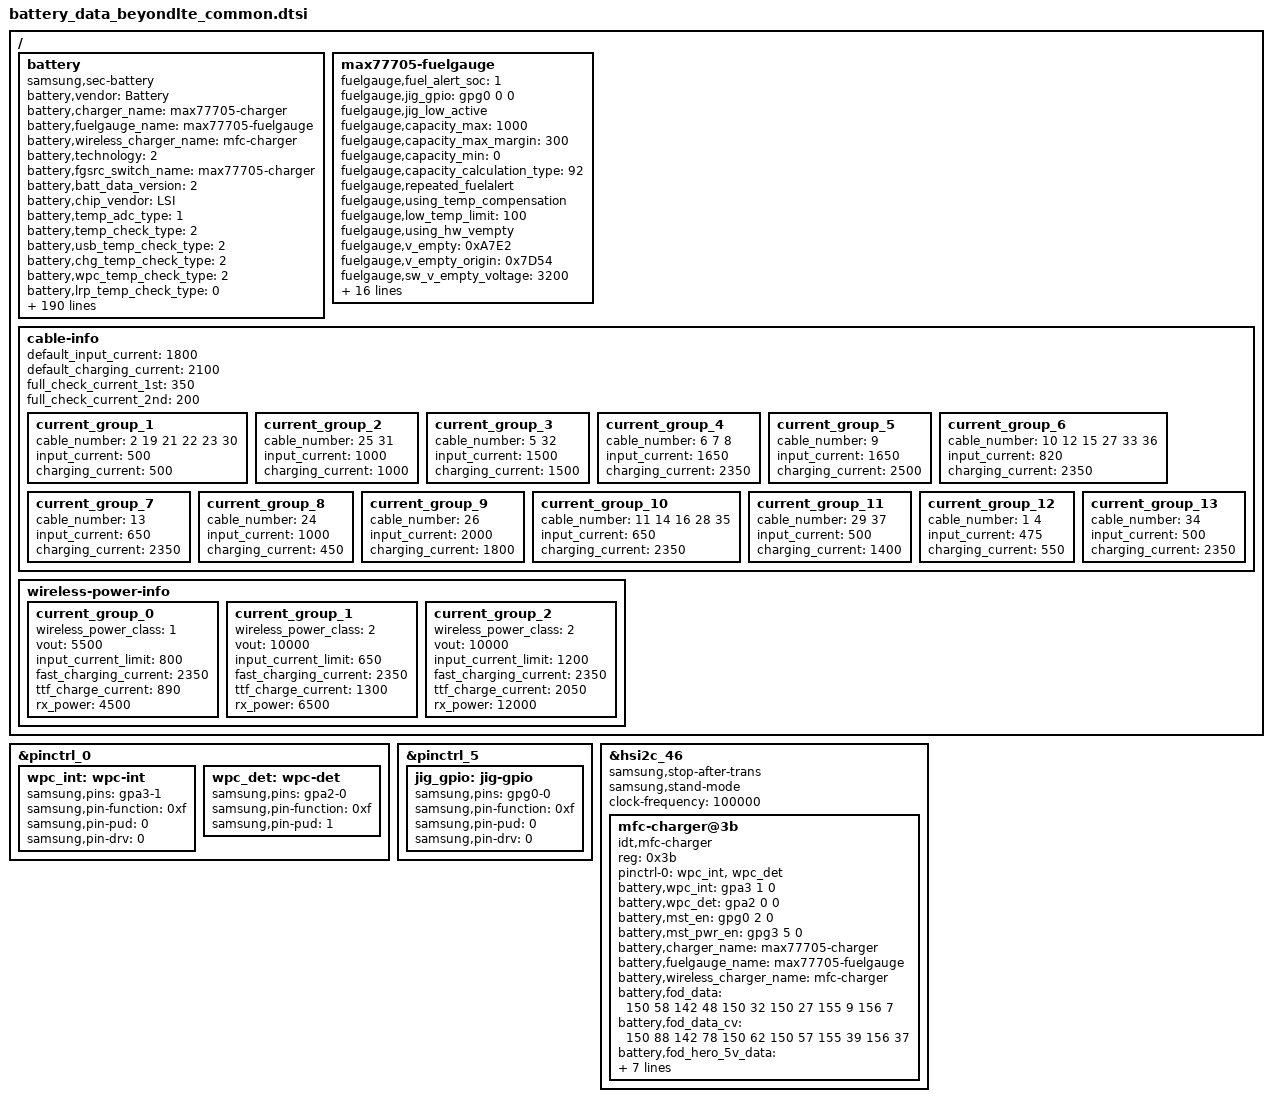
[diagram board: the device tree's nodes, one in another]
/*
 * SAMSUNG UNIVERSAL9820 board device tree source
 *
 * Copyright (c) 2018 Samsung Electronics Co., Ltd.
 *		http://www.samsung.com
 *
 * This program is free software; you can redistribute it and/or modify
 * it under the terms of the GNU General Public License version 2 as
 * published by the Free Software Foundation.
 */

/ {
	fragment@battery {
		target-path = "/";
		__overlay__ {
			battery {
				status = "okay";
				compatible = "samsung,sec-battery";

				pinctrl-names = "default";
				/* battery,irq_gpio = <&gpa1 6 0>; */

				battery,vendor = "Battery";
				battery,charger_name = "max77705-charger";
				battery,fuelgauge_name = "max77705-fuelgauge";
				battery,wireless_charger_name = "mfc-charger";
				battery,technology = <2>; /* POWER_SUPPLY_TECHNOLOGY_LION */
				battery,fgsrc_switch_name = "max77705-charger"; /* Fuelgauge voltage source */

				battery,batt_data_version = <2>;

				battery,chip_vendor = "LSI";
				battery,temp_adc_type = <1>; /* SEC_BATTERY_ADC_TYPE_AP */

				battery,temp_check_type = <2>; /* SEC_BATTERY_TEMP_CHECK_NONE */
				battery,usb_temp_check_type = <2>;
				battery,chg_temp_check_type = <2>;
				battery,wpc_temp_check_type = <2>;
				battery,lrp_temp_check_type = <0>;

				battery,thermal_source = <2>; /* SEC_BATTERY_THERMAL_SOURCE_ADC */
				battery,usb_thermal_source = <2>; /* SEC_BATTERY_THERMAL_SOURCE_ADC */
				battery,chg_thermal_source = <2>; /* SEC_BATTERY_THERMAL_SOURCE_ADC */
				battery,wpc_thermal_source = <2>; /* SEC_BATTERY_THERMAL_SOURCE_ADC */

				battery,polling_time = <10 30 30 30 3600>;

				battery,temp_table_adc = <328 378 437 504 585 680 788 914 1059 1224
					1407 1608 1828 2058 2291 2425 2747 2963 3153 3321 3467 3590 3689>;
				battery,temp_table_data = <900 850 800 750 700 650 600 550 500 450
					400 350 300 250 200 150 100 50 0 (-50) (-100) (-150) (-200)>;

				battery,usb_temp_table_adc = <294 346 408 482 567 667 780 911 1058 1224
					1405 1604 1816 2039 2259 2473 2688 2884 3060 3213 3346 3445 3544>;
				battery,usb_temp_table_data = <900 850 800 750 700 650 600 550 500 450
					400 350 300 250 200 150 100 50 0 (-50) (-100) (-150) (-200)>;

				battery,chg_temp_table_adc = <282 333 392 460 541 636 745 867 1016 1182
					1366 1562 1787 2011 2256 2466 2712 2931 3123 3296 3443 3570 3673>;
				battery,chg_temp_table_data = <900 850 800 750 700 650 600 550 500 450
					400 350 300 250 200 150 100 50 0 (-50) (-100) (-150) (-200)>;

				battery,wpc_temp_table_adc = <328 378 437 504 585 680 788 914 1059 1224
					1407 1608 1828 2058 2291 2425 2747 2963 3153 3321 3467 3590 3689>;
				battery,wpc_temp_table_data = <900 850 800 750 700 650 600 550 500 450
					400 350 300 250 200 150 100 50 0 (-50) (-100) (-150) (-200)>;

				battery,wireless_cc_cv = <85>;
				battery,wpc_cc_cv_vout = <5500>;
				battery,wpc_cv_call_vout = <5000>;
				battery,wpc_cc_call_vout = <5000>;
				battery,wpc_det = <&gpa2 0 0>;
				battery,wpc_int = <&gpa3 2 0>;
				battery,hv_vout_wa = <0x41>; /* WC vout 10.0V */
				battery,adc_check_count = <5>;

				battery,cable_check_type = <4>; /* SEC_BATTERY_CABLE_CHECK_PSY */
				battery,cable_source_type = <1>; /* SEC_BATTERY_CABLE_SOURCE_EXTERNAL */
				battery,polling_type = <1>; /* SEC_BATTERY_MONITOR_ALARM */
				battery,monitor_initial_count = <0>;

				battery,battery_check_type = <0>; /* SEC_BATTERY_CHECK_NONE */
				battery,check_count = <0>;
				battery,check_adc_max = <1440>;
				battery,check_adc_min = <0>;

				battery,ovp_uvlo_check_type = <3>; /* SEC_BATTERY_OVP_UVLO_CHGPOLLING */

				battery,temp_check_count = <1>;
				battery,temp_highlimit_threshold_event = <700>;
				battery,temp_highlimit_recovery_event = <680>;
				battery,temp_high_threshold_event = <500>;
				battery,temp_high_recovery_event = <480>;
				battery,temp_low_threshold_event = <0>;
				battery,temp_low_recovery_event = <20>;
				battery,temp_highlimit_threshold_normal = <700>;
				battery,temp_highlimit_recovery_normal = <680>;
				battery,temp_high_threshold_normal = <500>;
				battery,temp_high_recovery_normal = <480>;
				battery,temp_low_threshold_normal = <0>;
				battery,temp_low_recovery_normal = <20>;
				battery,temp_highlimit_threshold_lpm = <700>;
				battery,temp_highlimit_recovery_lpm = <680>;
				battery,temp_high_threshold_lpm = <500>;
				battery,temp_high_recovery_lpm = <480>;
				battery,temp_low_threshold_lpm = <0>;
				battery,temp_low_recovery_lpm = <20>;
				battery,wpc_high_threshold_normal = <450>;
				battery,wpc_high_recovery_normal = <430>;
				battery,wpc_low_threshold_normal = <0>;
				battery,wpc_low_recovery_normal = <20>;
				battery,tx_high_threshold = <450>;
				battery,tx_high_recovery = <400>;
				battery,tx_low_threshold = <0>;
				battery,tx_low_recovery = <50>;
				battery,full_check_type = <7>; /* SEC_BATTERY_FULLCHARGED_CHGPSY */
				battery,full_check_type_2nd = <7>; /* SEC_BATTERY_FULLCHARGED_CHGPSY */
				battery,full_check_count = <1>;
				battery,chg_gpio_full_check = <0>;
				battery,chg_polarity_full_check = <1>;

				battery,chg_high_temp = <460>;
				battery,chg_high_temp_recovery = <440>;
				battery,chg_input_limit_current = <1000>;
				battery,chg_charging_limit_current = <1400>;

				battery,wpc_temp_control_source = <1>; /* TEMP_CONTROL_SOURCE_BAT_THM = WPC_THM */
				battery,wpc_high_temp = <380>;
				battery,wpc_high_temp_recovery = <360>;
				battery,wpc_input_limit_current = <600>;
				battery,wpc_charging_limit_current = <1000>;
				battery,wpc_temp_lcd_on_control_source = <1>; /* TEMP_CONTROL_SOURCE_BAT_THM = WPC_THM */
				battery,wpc_lcd_on_high_temp = <380>;
				battery,wpc_lcd_on_high_temp_rec = <360>;
				battery,wpc_lcd_on_input_limit_current = <450>;

				battery,wpc_store_high_temp = <360>;
				battery,wpc_store_high_temp_recovery = <340>;
				battery,wpc_store_lcd_on_high_temp = <360>;
				battery,wpc_store_lcd_on_high_temp_rec = <300>;
				battery,wpc_store_lcd_on_charging_limit_current = <400>;

				battery,sleep_mode_limit_current = <800>;
				battery,wc_full_input_limit_current = <100>;

				battery,mix_high_temp = <420>;
				battery,mix_high_chg_temp = <500>;
				battery,mix_high_temp_recovery = <390>;

				/* SEC_BATTERY_FULL_CONDITION_NOTIMEFULL | SEC_BATTERY_FULL_CONDITION_VCELL */
				battery,full_condition_type = <9>;
				battery,full_condition_soc = <93>;
				battery,full_condition_vcell = <4250>;

				battery,recharge_check_count = <1>;
				battery,recharge_condition_type = <4>; /* SEC_BATTERY_RECHARGE_CONDITION_VCELL */
				battery,recharge_condition_soc = <98>;
				battery,recharge_condition_vcell = <4280>;

				battery,charging_total_time = <14400>;
				battery,hv_charging_total_time = <10800>;
				battery,normal_charging_total_time = <18000>;
				battery,usb_charging_total_time = <36000>;
				battery,recharging_total_time = <5400>;
				battery,charging_reset_time = <0>;

				battery,chg_float_voltage = <4350>;

				battery,swelling_high_temp_block = <410>;
				battery,swelling_high_temp_recov = <390>;
				battery,swelling_low_temp_block_1st = <150>;
				battery,swelling_low_temp_recov_1st = <170>;
				battery,swelling_low_temp_block_2nd = <50>;
				battery,swelling_low_temp_recov_2nd = <70>;

				battery,swelling_low_temp_current = <750>;	/* 0.3C */
				battery,swelling_low_temp_current_2nd = <330>;	/* 0.1C */
				battery,swelling_low_temp_topoff = <200>;	/* 0.05C */
				battery,swelling_high_temp_current = <1150>;	/* 0.45C */
				battery,swelling_high_temp_topoff = <200>;	/* 0.05C */
				battery,swelling_wc_high_temp_current = <750>;	/* 0.3C */
				battery,swelling_wc_low_temp_current = <750>;	/* 0.3C */
				battery,swelling_wc_low_temp_current_2nd = <330>;	/* 0.3C */

				battery,swelling_drop_float_voltage = <4150>;
				battery,swelling_high_rechg_voltage = <4000>;
				battery,swelling_low_rechg_voltage = <4000>;
				battery,wa_float_voltage = <4050>;

				battery,siop_event_check_type = <1>;
				battery,siop_call_cv_current = <300>;
				battery,siop_call_cc_current = <300>;

				battery,siop_input_limit_current = <1200>;
				battery,siop_charging_limit_current = <1000>;
				battery,siop_hv_input_limit_current = <700>;
				battery,siop_hv_charging_limit_current = <1000>;

				battery,siop_wireless_input_limit_current = <600>;
				battery,siop_wireless_charging_limit_current = <850>;
				battery,siop_hv_wireless_input_limit_current = <600>;
				battery,siop_hv_wireless_charging_limit_current = <850>;
				battery,siop_store_hv_wireless_input_limit_current = <450>;

				battery,ttf_hv_charge_current = <2500>;
				battery,ttf_hv_12v_wireless_charge_current = <2050>;
				battery,ttf_hv_wireless_charge_current = <1300>;
				battery,ttf_wireless_charge_current = <890>;

				battery,rp_current_rp1 = <500>;
				battery,rp_current_rp2 = <1500>;
				battery,rp_current_rp3 = <3000>;
				battery,rp_current_rdu_rp3 = <2100>;
				battery,rp_current_abnormal_rp3 = <1800>;

				battery,pd_charging_charge_power = <15000>;
				battery,max_charging_current = <2350>;
				battery,battery_full_capacity = <3300>;

				/* cycle, chg_float_voltage, recharge_condition_vcell, full_condition_vcell, full_condition_soc, step charging condition */
				battery,age_data = <0 4350 4280 4250 93 45
						300 4330 4260 4230 92 45
						400 4310 4240 4210 91 45
						700 4290 4220 4190 90 45
						1000 4240 4170 4140 89 45>;

				battery,health_condition = <
						/* CYCLE ASOC */
						900 75	/* GOOD */
						1200 65 /* NORMAL */
						1500 55 /* AGED */
						>;

				/* step charging option */
				battery,step_charging_type = <0x3E>;
				battery,step_charging_charge_power = <12000>;
				battery,step_charging_condition = <45 100>;
				battery,step_charging_condition_curr = <2350 2350>;
				battery,step_charging_current = <3150 2350>;
				battery,step_charging_float_voltage = <4150 4350>;

				battery,pre_afc_input_current = <500>; /* mA */
				battery,prepare_ta_delay = <0>; /* msec */

				battery,max_input_voltage = <9000>; /* mV */
				battery,max_input_current = <3000>;  /* mA */

				battery,enable_sysovlo_irq;
				battery,enable_noise_wa;

				battery,standard_curr = <2350>;
				battery,expired_time = <10800>;
				battery,recharging_expired_time = <5400>;

				battery,cisd_max_voltage_thr = <4400>; /* battery ovp detection voltage */

				battery,cisd_alg_index = <8>;
				battery,ignore_cisd_index = <0 0>; /* Do not use AFC_FAIL to DROP_VALUE */
				battery,ignore_cisd_index_d = <0 80>; /* Do not use AFC_FAIL_PER_DAY to DROP_VALUE_PER_DAY */

				battery,tx_stop_capacity = <30>;
				battery,tx_minduty_default = <20>;
				battery,tx_minduty_5V = <50>;

				battery,tx_uno_iout = <1500>;
				battery,tx_mfc_iout_gear = <1500>;
				battery,tx_mfc_iout_phone = <1100>;
				battery,tx_mfc_iout_phone_5v = <300>;
				battery,tx_mfc_iout_lcd_on = <900>;

				io-channels = <&exynos_adc 4>, <&exynos_adc 3>, <&exynos_adc 11>, <&exynos_adc 4>, <&exynos_adc 1>;
				io-channel-names = "adc-temp", "adc-chg-temp", "adc-in-bat", "adc-wpc-temp", "adc-usb-temp";
#io-channel-cells = <5>;
				io-channel-ranges;
			};

			max77705-fuelgauge {
				status = "okay";
				fuelgauge,fuel_alert_soc = <1>;
				fuelgauge,jig_gpio = <&gpg0 0 0>;
				fuelgauge,jig_low_active;
				fuelgauge,capacity_max = <1000>;
				fuelgauge,capacity_max_margin = <300>;
				fuelgauge,capacity_min = <0>;
				fuelgauge,capacity_calculation_type = <92>;
				fuelgauge,repeated_fuelalert;
				fuelgauge,using_temp_compensation;
				fuelgauge,low_temp_limit = <100>;
				fuelgauge,using_hw_vempty;
				fuelgauge,v_empty = <0xA7E2>; /* Empty: 3260mV, Recover: 3480mV */
				fuelgauge,v_empty_origin = <0x7D54>; /* Empty: 2500mV, Recover: 3360mV */
				fuelgauge,sw_v_empty_voltage = <3200>;
				fuelgauge,sw_v_empty_voltage_cisd = <3100>;
				fuelgauge,sw_v_empty_recover_voltage = <3480>;
				fuelgauge,fg_resistor = <2>;
				fuelgauge,capacity = <0x0CC9>;
				/* fullcapnom(=capacity), dPacc, dQacc,  rcomp0, tempco */
				fuelgauge,fg_reset_wa_data = <0xCC9 0x3200 0x322 0x30 0x141F>;
				/*fuelgauge,auto_discharge_en;*/
				fuelgauge,discharge_temp_threshold = <600>;
				fuelgauge,discharge_volt_threshold = <4200>;

				fuelgauge,lost_soc_trig_soc = <1000>; /* 100.0% */
				fuelgauge,lost_soc_trig_d_soc = <20>; /* 2% */
				fuelgauge,lost_soc_trig_scale = <2>; /* 2x */
				fuelgauge,lost_soc_guarantee_soc = <30>; /* 3.0% */
				fuelgauge,lost_soc_min_vol = <3200>; /* 3200mV */

				fuelgauge,ttf_capacity = <3000>;
				fuelgauge,cv_data = <
					2324	784	2253
					2200	802	2162
					2030	820	2070
					1740	847	1904
					1545	868	1765
					1354	887	1612
					1135	907	1429
					949	924	1246
					764	943	1003
					653	957	791
					543	969	578
					452	982	282
					399	992	122
					360	1000	0
					>;
			};

			/* sec_battery_cable
			 *   0	UNKNOWN,
			 *   1	NONE,
			 *   2	PREPARE_TA,
			 *   3	TA,
			 *   4	USB,
			 *   5	USB_CDP,
			 *   6	9V_TA,
			 *   7	9V_ERR,
			 *   8	9V_UNKNOWN,
			 *   9	12V_TA,
			 *  10	WIRELESS,
			 *  11	HV_WIRELESS,
			 *  12	PMA_WIRELESS,
			 *  13	WIRELESS_PACK,
			 *  14	WIRELESS_HV_PACK,
			 *  15	WIRELESS_STAND,
			 *  16	WIRELESS_HV_STAND,
			 *  17	QC20,
			 *  18	QC30,
			 *  19	PDIC,
			 *  20	UARTOFF,
			 *  21	OTG,
			 *  22	LAN_HUB,
			 *  23	POWER_SHARING,
			 *  24	HMT_CONNECTED,
			 *  25	HMT_CHARGE,
			 *  26	HV_TA_CHG_LIMIT,
			 *  27	WIRELESS_VEHICLE,
			 *  28	WIRELESS_HV_VEHICLE,
			 *  29	PREPARE_WIRELESS_HV,
			 *  30	TIMEOUT,
			 *  31	SMART_OTG,
			 *  32	SMART_NOTG,
			 *  33	WIRELESS_TX,
			 *  34	HV_WIRELESS_20,
			 *  35	HV_WIRELESS_20_LIMIT,
			 *  36	WIRELESS_FAKE,
			 *  37  PREPARE_WIRELESS_20,
			 *  38	CABLE_PDIC_APDO,
			 *  39	CABLE_MAX,
			 */

			cable-info {
				default_input_current = <1800>;
				default_charging_current = <2100>;
				full_check_current_1st = <350>;
				full_check_current_2nd = <200>;

				current_group_1 {
					cable_number = <2 19 21 22 23 30>;
					input_current = <500>;
					charging_current = <500>;
				};
				current_group_2 {
					cable_number = <25 31>;
					input_current = <1000>;
					charging_current = <1000>;
				};
				current_group_3 {
					cable_number = <5 32>;
					input_current = <1500>;
					charging_current = <1500>;
				};
				current_group_4 {
					cable_number = <6 7 8>;
					input_current = <1650>;
					charging_current = <2350>;
				};
				current_group_5 {
					cable_number = <9>;
					input_current = <1650>;
					charging_current = <2500>;
				};
				current_group_6 {
					cable_number = <10 12 15 27 33 36>;
					input_current = <820>;
					charging_current = <2350>;
				};
				current_group_7 {
					cable_number = <13>;
					input_current = <650>;
					charging_current = <2350>;
				};
				current_group_8 {
					cable_number = <24>;
					input_current = <1000>;
					charging_current = <450>;
				};
				current_group_9 {
					cable_number = <26>;
					input_current = <2000>;
					charging_current = <1800>;
				};
				current_group_10 {
					cable_number = <11 14 16 28 35>;
					input_current = <650>;
					charging_current = <2350>;
				};
				current_group_11 {
					cable_number = <29 37>;
					input_current = <500>;
					charging_current = <1400>;
				};
				current_group_12 {
					cable_number = <1 4>;
					input_current = <475>;
					charging_current = <550>;
				};
				current_group_13 {
					cable_number = <34>;
					input_current = <500>;
					charging_current = <2350>;
				};
			};
			wireless-power-info {
				current_group_0 {
					wireless_power_class = <1>;
					vout = <5500>;
					input_current_limit = <800>;
					fast_charging_current = <2350>;
					ttf_charge_current = <890>;
					rx_power = <4500>;
				};
				current_group_1 {
					wireless_power_class = <2>;
					vout = <10000>;
					input_current_limit = <650>;
					fast_charging_current = <2350>;
					ttf_charge_current = <1300>;
					rx_power = <6500>;
				};
				current_group_2 {
					wireless_power_class = <2>;
					vout = <10000>;
					input_current_limit = <1200>;
					fast_charging_current = <2350>;
					ttf_charge_current = <2050>;
					rx_power = <12000>;
				};
			};
		}; /* end of __overlay__ */
	}; /* end of fragment */
};

&pinctrl_0 {
	wpc_int: wpc-int {
		 samsung,pins = "gpa3-1";
		 samsung,pin-function = <0xf>;
		 samsung,pin-pud = <0>;
		 samsung,pin-drv = <0>;
	 };

	wpc_det: wpc-det {
		 samsung,pins = "gpa2-0";
		 samsung,pin-function = <0xf>;
		 samsung,pin-pud = <1>;
	 };
};

&pinctrl_5 {
	jig_gpio: jig-gpio {
		samsung,pins = "gpg0-0";
		samsung,pin-function = <0xf>;
		samsung,pin-pud = <0>;
		samsung,pin-drv = <0>;
	};
};

&hsi2c_46 {
	#address-cells = <1>;
	#size-cells = <0>;
	status = "okay";
	samsung,stop-after-trans;
	samsung,stand-mode;
	clock-frequency = <100000>;

	mfc-charger@3b {
		compatible = "idt,mfc-charger";
		reg = <0x3b>;
		status = "okay";

		pinctrl-names = "default";
		pinctrl-0 = <&wpc_int &wpc_det>;

		battery,wpc_int = <&gpa3 1 0>;
		battery,wpc_det = <&gpa2 0 0>;
		battery,mst_en = <&gpg0 2 0>;
		battery,mst_pwr_en = <&gpg3 5 0>;

		battery,charger_name = "max77705-charger";
		battery,fuelgauge_name = "max77705-fuelgauge";
		battery,wireless_charger_name = "mfc-charger";
		battery,fod_data = <150 58 142 48 150 32 150 27 155 9 156 7>;
		battery,fod_data_cv = <150 88 142 78 150 62 150 57 155 39 156 37>;
		battery,fod_hero_5v_data = <150 2 142 (-6) 150 (-20) 150 (-28) 165 185 156 (-39)>;
		battery,wc_cover_rpp = <0x44>;
		battery,oc_fod1 = <1100>;
		battery,tx_gear_min_op_freq_delay = <4000>;
		battery,wireless20_vout_list = <8>; /* WIRELESS_VOUT_10V*/
		battery,wireless20_vrect_list = <10>; /* MFC_AFC_CONF_12V_TX*/
		battery,wireless20_max_power_list = <2>; /* SEC_WIRELESS_RX_POWER_12W*/
	};
};

